VERSION ""

NS_ :

BS_:

BU_: CLUSTER FCU1 FCU2 FDC1 FDC2 HMS TBOX Tester VCU

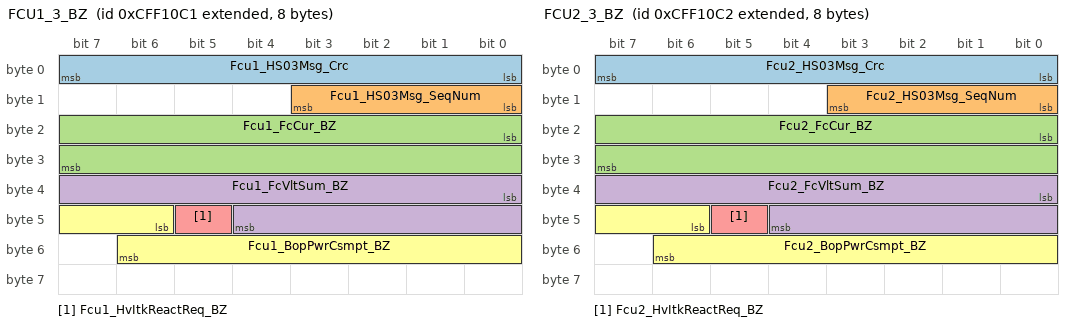
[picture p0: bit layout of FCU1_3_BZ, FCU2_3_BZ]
BO_ 2365526209 FCU1_3_BZ: 8 FCU1
 SG_ Fcu1_HS03Msg_Crc : 0|8@1+ (1,0) [0|255] "" VCU
 SG_ Fcu1_HS03Msg_SeqNum : 8|4@1+ (1,0) [0|15] "" VCU
 SG_ Fcu1_FcCur_BZ : 16|16@1+ (0.01,0) [0|655.35] "A" VCU
 SG_ Fcu1_FcVltSum_BZ : 32|13@1+ (0.1,0) [0|819.1] "V" VCU
 SG_ Fcu1_HvItkReactReq_BZ : 45|1@1+ (1,0) [0|1] "" VCU
 SG_ Fcu1_BopPwrCsmpt_BZ : 46|9@1+ (0.1,-5) [-5|46.1] "kW" VCU

BO_ 2365526210 FCU2_3_BZ: 8 FCU2
 SG_ Fcu2_HS03Msg_Crc : 0|8@1+ (1,0) [0|255] "" VCU
 SG_ Fcu2_HS03Msg_SeqNum : 8|4@1+ (1,0) [0|15] "" VCU
 SG_ Fcu2_FcCur_BZ : 16|16@1+ (0.01,0) [0|655.35] "A" VCU
 SG_ Fcu2_FcVltSum_BZ : 32|13@1+ (0.1,0) [0|819.1] "V" VCU
 SG_ Fcu2_HvItkReactReq_BZ : 45|1@1+ (1,0) [0|1] "" VCU
 SG_ Fcu2_BopPwrCsmpt_BZ : 46|9@1+ (0.1,-5) [-5|46.1] "kW" VCU

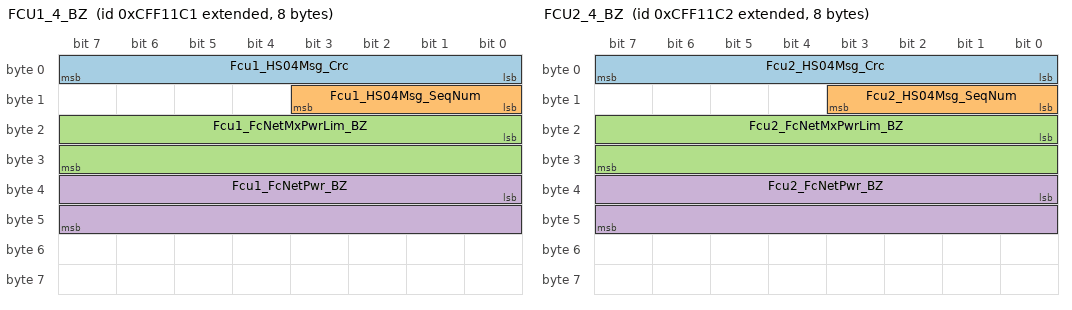
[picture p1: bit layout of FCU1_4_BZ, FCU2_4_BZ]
BO_ 2365526465 FCU1_4_BZ: 8 FCU1
 SG_ Fcu1_HS04Msg_Crc : 0|8@1+ (1,0) [0|255] "" VCU
 SG_ Fcu1_HS04Msg_SeqNum : 8|4@1+ (1,0) [0|15] "" VCU
 SG_ Fcu1_FcNetMxPwrLim_BZ : 16|16@1+ (0.1,0) [0|255] "kw" VCU
 SG_ Fcu1_FcNetPwr_BZ : 32|16@1+ (0.1,0) [0|255] "kw" VCU

BO_ 2365526466 FCU2_4_BZ: 8 FCU2
 SG_ Fcu2_HS04Msg_Crc : 0|8@1+ (1,0) [0|255] "" VCU
 SG_ Fcu2_HS04Msg_SeqNum : 8|4@1+ (1,0) [0|15] "" VCU
 SG_ Fcu2_FcNetMxPwrLim_BZ : 16|16@1+ (0.1,0) [0|255] "kw" VCU
 SG_ Fcu2_FcNetPwr_BZ : 32|16@1+ (0.1,0) [0|255] "kw" VCU

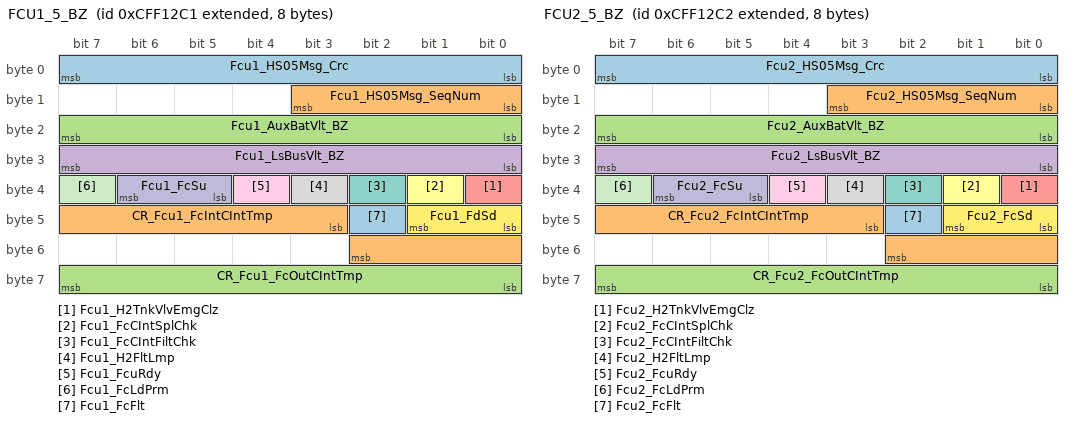
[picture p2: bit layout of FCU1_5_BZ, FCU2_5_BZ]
BO_ 2365526721 FCU1_5_BZ: 8 FCU1
 SG_ Fcu1_HS05Msg_Crc : 0|8@1+ (1,0) [0|255] "" VCU
 SG_ Fcu1_HS05Msg_SeqNum : 8|4@1+ (1,0) [0|15] "" VCU
 SG_ Fcu1_AuxBatVlt_BZ : 16|8@1+ (0.1,0) [0|25.5] "V" VCU
 SG_ Fcu1_LsBusVlt_BZ : 24|8@1+ (2,0) [0|510] "V" VCU
 SG_ Fcu1_H2TnkVlvEmgClz : 32|1@1+ (1,0) [0|1] "" VCU
 SG_ Fcu1_FcCIntSplChk : 33|1@1+ (1,0) [0|1] "" VCU
 SG_ Fcu1_FcCIntFiltChk : 34|1@1+ (1,0) [0|1] "" VCU
 SG_ Fcu1_H2FltLmp : 35|1@1+ (1,0) [0|1] "" VCU
 SG_ Fcu1_FcuRdy : 36|1@1+ (1,0) [0|1] "" VCU
 SG_ Fcu1_FcSu : 37|2@1+ (1,0) [0|1] "" VCU
 SG_ Fcu1_FcLdPrm : 39|1@1+ (1,0) [0|1] "" VCU
 SG_ Fcu1_FdSd : 40|2@1+ (1,0) [0|1] "" VCU
 SG_ Fcu1_FcFlt : 42|1@1+ (1,0) [0|1] "" VCU
 SG_ CR_Fcu1_FcIntCIntTmp : 43|8@1+ (1,0) [-128|127] "℃" VCU
 SG_ CR_Fcu1_FcOutCIntTmp : 56|8@1+ (1,0) [-128|127] "℃" VCU

BO_ 2365526722 FCU2_5_BZ: 8 FCU2
 SG_ Fcu2_HS05Msg_Crc : 0|8@1+ (1,0) [0|255] "" VCU
 SG_ Fcu2_HS05Msg_SeqNum : 8|4@1+ (1,0) [0|15] "" VCU
 SG_ Fcu2_AuxBatVlt_BZ : 16|8@1+ (0.1,0) [0|25.5] "V" VCU
 SG_ Fcu2_LsBusVlt_BZ : 24|8@1+ (2,0) [0|510] "V" VCU
 SG_ Fcu2_H2TnkVlvEmgClz : 32|1@1+ (1,0) [0|1] "" VCU
 SG_ Fcu2_FcCIntSplChk : 33|1@1+ (1,0) [0|1] "" VCU
 SG_ Fcu2_FcCIntFiltChk : 34|1@1+ (1,0) [0|1] "" VCU
 SG_ Fcu2_H2FltLmp : 35|1@1+ (1,0) [0|1] "" VCU
 SG_ Fcu2_FcuRdy : 36|1@1+ (1,0) [0|1] "" VCU
 SG_ Fcu2_FcSu : 37|2@1+ (1,0) [0|1] "" VCU
 SG_ Fcu2_FcLdPrm : 39|1@1+ (1,0) [0|1] "" VCU
 SG_ Fcu2_FcSd : 40|2@1+ (1,0) [0|1] "" VCU
 SG_ Fcu2_FcFlt : 42|1@1+ (1,0) [0|1] "" VCU
 SG_ CR_Fcu2_FcIntCIntTmp : 43|8@1+ (1,0) [-128|127] "℃" VCU
 SG_ CR_Fcu2_FcOutCIntTmp : 56|8@1+ (1,0) [-128|127] "℃" VCU

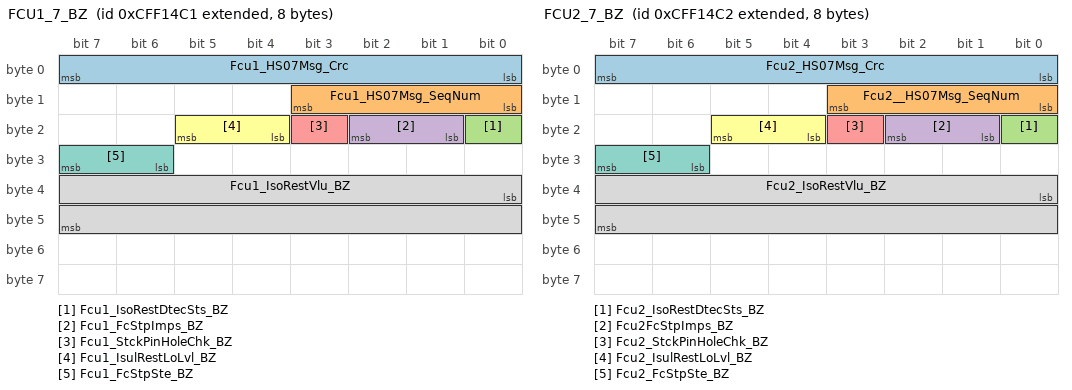
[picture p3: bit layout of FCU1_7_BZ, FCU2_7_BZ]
BO_ 2365527233 FCU1_7_BZ: 8 FCU1
 SG_ Fcu1_HS07Msg_Crc : 0|8@1+ (1,0) [0|255] "" VCU
 SG_ Fcu1_HS07Msg_SeqNum : 8|4@1+ (1,0) [0|15] "" VCU
 SG_ Fcu1_IsoRestDtecSts_BZ : 16|1@1+ (1,0) [0|1] "" VCU
 SG_ Fcu1_FcStpImps_BZ : 17|2@1+ (1,0) [0|3] "" VCU
 SG_ Fcu1_StckPinHoleChk_BZ : 19|1@1+ (1,0) [0|1] "" VCU
 SG_ Fcu1_IsulRestLoLvl_BZ : 20|2@1+ (1,0) [0|3] "" VCU
 SG_ Fcu1_FcStpSte_BZ : 30|2@1+ (1,0) [0|3] "" VCU
 SG_ Fcu1_IsoRestVlu_BZ : 32|16@1+ (1,0) [0|65535] "㏀" VCU

BO_ 2365527234 FCU2_7_BZ: 8 FCU2
 SG_ Fcu2_HS07Msg_Crc : 0|8@1+ (1,0) [0|255] "" VCU
 SG_ Fcu2__HS07Msg_SeqNum : 8|4@1+ (1,0) [0|15] "" VCU
 SG_ Fcu2_IsoRestDtecSts_BZ : 16|1@1+ (1,0) [0|1] "" VCU
 SG_ Fcu2FcStpImps_BZ : 17|2@1+ (1,0) [0|3] "" VCU
 SG_ Fcu2_StckPinHoleChk_BZ : 19|1@1+ (1,0) [0|1] "" VCU
 SG_ Fcu2_IsulRestLoLvl_BZ : 20|2@1+ (1,0) [0|3] "" VCU
 SG_ Fcu2_FcStpSte_BZ : 30|2@1+ (1,0) [0|3] "" VCU
 SG_ Fcu2_IsoRestVlu_BZ : 32|16@1+ (1,0) [0|65535] "㏀" VCU

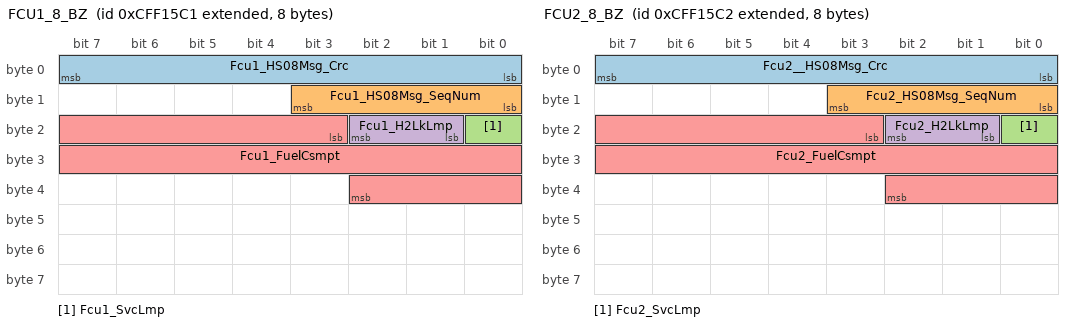
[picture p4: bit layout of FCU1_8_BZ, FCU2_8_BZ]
BO_ 2365527489 FCU1_8_BZ: 8 FCU1
 SG_ Fcu1_HS08Msg_Crc : 0|8@1+ (1,0) [0|255] "" VCU
 SG_ Fcu1_HS08Msg_SeqNum : 8|4@1+ (1,0) [0|15] "" VCU
 SG_ Fcu1_SvcLmp : 16|1@1+ (1,0) [0|1] "" VCU
 SG_ Fcu1_H2LkLmp : 17|2@1+ (1,0) [0|3] "" VCU
 SG_ Fcu1_FuelCsmpt : 19|16@1+ (0.01,0) [0|655.35] "mg" VCU

BO_ 2365527490 FCU2_8_BZ: 8 FCU2
 SG_ Fcu2__HS08Msg_Crc : 0|8@1+ (1,0) [0|255] "" VCU
 SG_ Fcu2_HS08Msg_SeqNum : 8|4@1+ (1,0) [0|15] "" VCU
 SG_ Fcu2_SvcLmp : 16|1@1+ (1,0) [0|1] "" VCU
 SG_ Fcu2_H2LkLmp : 17|2@1+ (1,0) [0|3] "" VCU
 SG_ Fcu2_FuelCsmpt : 19|16@1+ (0.01,0) [0|655.35] "mg" VCU

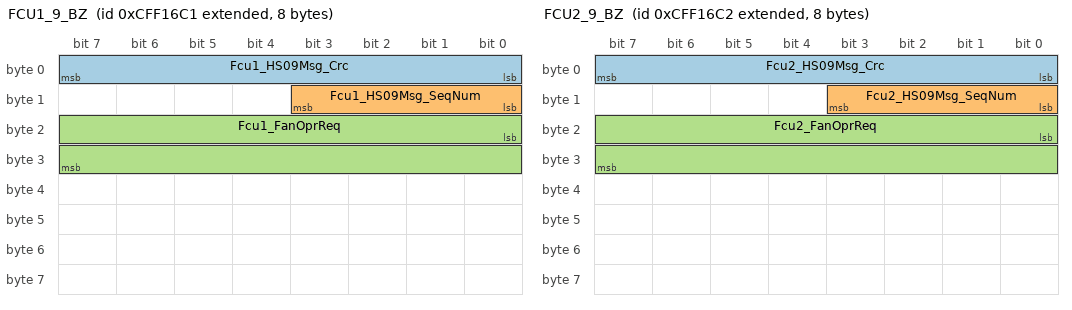
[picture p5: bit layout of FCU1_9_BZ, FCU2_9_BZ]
BO_ 2365527745 FCU1_9_BZ: 8 FCU1
 SG_ Fcu1_HS09Msg_Crc : 0|8@1+ (1,0) [0|255] "" VCU
 SG_ Fcu1_HS09Msg_SeqNum : 8|4@1+ (1,0) [0|15] "" VCU
 SG_ Fcu1_FanOprReq : 16|16@1+ (1,0) [0|100] "%" VCU

BO_ 2365527746 FCU2_9_BZ: 8 FCU2
 SG_ Fcu2_HS09Msg_Crc : 0|8@1+ (1,0) [0|255] "" VCU
 SG_ Fcu2_HS09Msg_SeqNum : 8|4@1+ (1,0) [0|15] "" VCU
 SG_ Fcu2_FanOprReq : 16|16@1+ (1,0) [0|100] "%" VCU

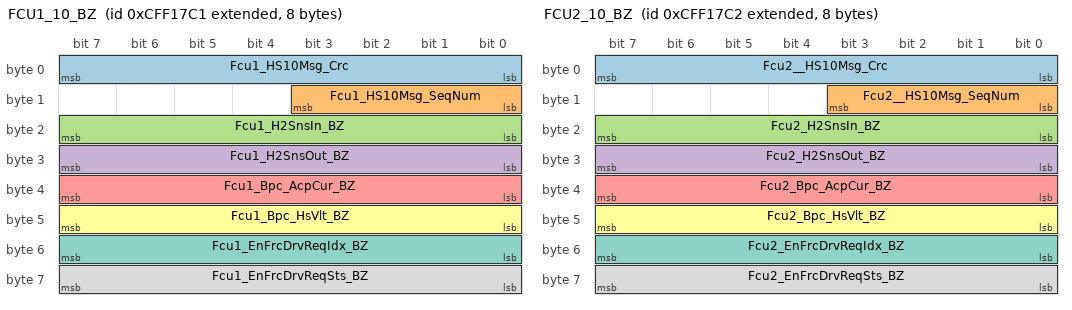
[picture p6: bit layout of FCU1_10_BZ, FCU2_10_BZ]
BO_ 2365528001 FCU1_10_BZ: 8 FCU1
 SG_ Fcu1_HS10Msg_Crc : 0|8@1+ (1,0) [0|255] "" VCU
 SG_ Fcu1_HS10Msg_SeqNum : 8|4@1+ (1,0) [0|15] "" VCU
 SG_ Fcu1_H2SnsIn_BZ : 16|8@1+ (0.02,0) [0|5.1] "%" VCU
 SG_ Fcu1_H2SnsOut_BZ : 24|8@1+ (0.02,0) [0|5.1] "%" VCU
 SG_ Fcu1_Bpc_AcpCur_BZ : 32|8@1+ (0.5,0) [-64|63.6] "A" VCU
 SG_ Fcu1_Bpc_HsVlt_BZ : 40|8@1+ (2,0) [0|510] "V" VCU
 SG_ Fcu1_EnFrcDrvReqIdx_BZ : 48|8@1+ (1,0) [0|255] "enum" VCU
 SG_ Fcu1_EnFrcDrvReqSts_BZ : 56|8@1+ (1,0) [0|255] "enum" VCU

BO_ 2365528002 FCU2_10_BZ: 8 FCU2
 SG_ Fcu2__HS10Msg_Crc : 0|8@1+ (1,0) [0|255] "" VCU
 SG_ Fcu2__HS10Msg_SeqNum : 8|4@1+ (1,0) [0|15] "" VCU
 SG_ Fcu2_H2SnsIn_BZ : 16|8@1+ (0.02,0) [0|5.1] "%" VCU
 SG_ Fcu2_H2SnsOut_BZ : 24|8@1+ (0.02,0) [0|5.1] "%" VCU
 SG_ Fcu2_Bpc_AcpCur_BZ : 32|8@1+ (0.5,0) [-64|63.6] "A" VCU
 SG_ Fcu2_Bpc_HsVlt_BZ : 40|8@1+ (2,0) [0|510] "V" VCU
 SG_ Fcu2_EnFrcDrvReqIdx_BZ : 48|8@1+ (1,0) [0|255] "enum" VCU
 SG_ Fcu2_EnFrcDrvReqSts_BZ : 56|8@1+ (1,0) [0|255] "enum" VCU

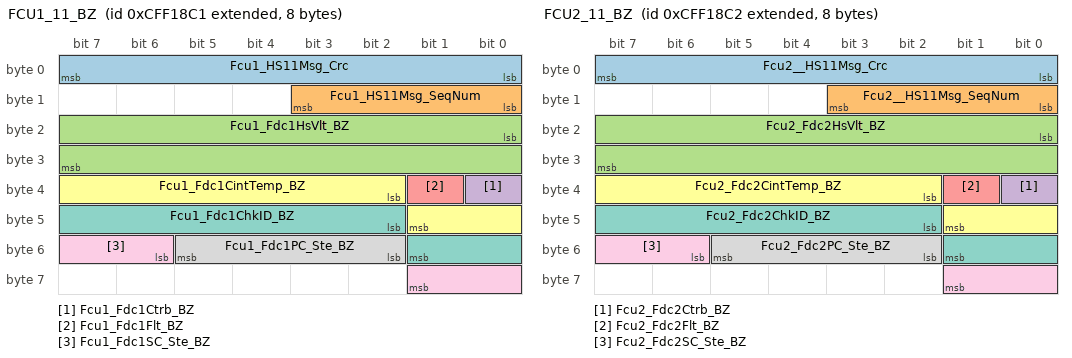
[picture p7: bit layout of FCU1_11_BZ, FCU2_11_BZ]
BO_ 2365528257 FCU1_11_BZ: 8 FCU1
 SG_ Fcu1_HS11Msg_Crc : 0|8@1+ (1,0) [0|255] "" VCU
 SG_ Fcu1_HS11Msg_SeqNum : 8|4@1+ (1,0) [0|15] "" VCU
 SG_ Fcu1_Fdc1HsVlt_BZ : 16|16@1+ (0.1,0) [0|1000] "" VCU
 SG_ Fcu1_Fdc1Ctrb_BZ : 32|1@1+ (1,0) [0|1] "" VCU
 SG_ Fcu1_Fdc1Flt_BZ : 33|1@1+ (1,0) [0|1] "" VCU
 SG_ Fcu1_Fdc1CintTemp_BZ : 34|8@1+ (1,-40) [-40|200] "" VCU
 SG_ Fcu1_Fdc1ChkID_BZ : 42|8@1+ (1,0) [0|255] "" VCU
 SG_ Fcu1_Fdc1PC_Ste_BZ : 50|4@1+ (1,0) [0|15] "" VCU
 SG_ Fcu1_Fdc1SC_Ste_BZ : 54|4@1+ (1,0) [0|15] "" VCU

BO_ 2365528258 FCU2_11_BZ: 8 FCU2
 SG_ Fcu2__HS11Msg_Crc : 0|8@1+ (1,0) [0|255] "" VCU
 SG_ Fcu2__HS11Msg_SeqNum : 8|4@1+ (1,0) [0|15] "" VCU
 SG_ Fcu2_Fdc2HsVlt_BZ : 16|16@1+ (0.1,0) [0|1000] "" VCU
 SG_ Fcu2_Fdc2Ctrb_BZ : 32|1@1+ (1,0) [0|1] "" VCU
 SG_ Fcu2_Fdc2Flt_BZ : 33|1@1+ (1,0) [0|1] "" VCU
 SG_ Fcu2_Fdc2CintTemp_BZ : 34|8@1+ (1,-40) [-40|200] "" VCU
 SG_ Fcu2_Fdc2ChkID_BZ : 42|8@1+ (1,0) [0|255] "" VCU
 SG_ Fcu2_Fdc2PC_Ste_BZ : 50|4@1+ (1,0) [0|15] "" VCU
 SG_ Fcu2_Fdc2SC_Ste_BZ : 54|4@1+ (1,0) [0|15] "" VCU

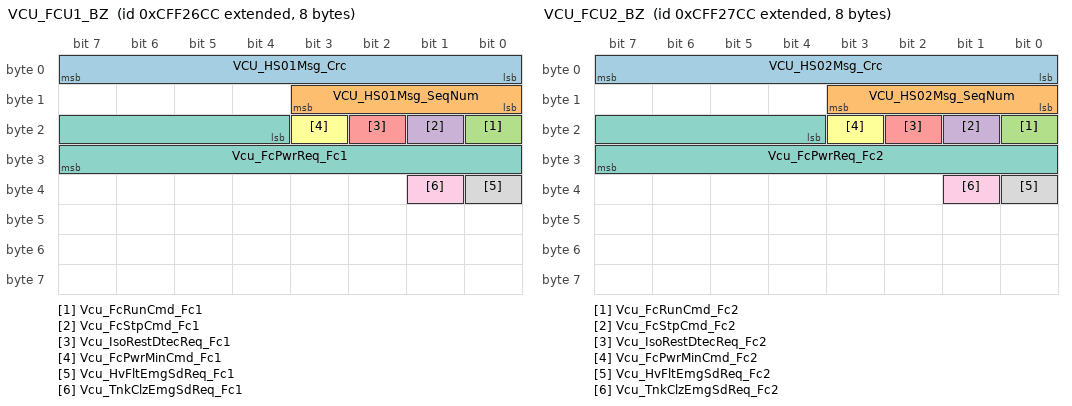
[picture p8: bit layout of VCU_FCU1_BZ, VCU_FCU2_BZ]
BO_ 2365531852 VCU_FCU1_BZ: 8 VCU
 SG_ VCU_HS01Msg_Crc : 0|8@1+ (1,0) [0|255] "" FCU1
 SG_ VCU_HS01Msg_SeqNum : 8|4@1+ (1,0) [0|15] "" FCU1
 SG_ Vcu_FcRunCmd_Fc1 : 16|1@1+ (1,0) [0|1] "" FCU1
 SG_ Vcu_FcStpCmd_Fc1 : 17|1@1+ (1,0) [0|1] "" FCU1
 SG_ Vcu_IsoRestDtecReq_Fc1 : 18|1@1+ (1,0) [0|1] "" FCU1
 SG_ Vcu_FcPwrMinCmd_Fc1 : 19|1@1+ (1,0) [0|1] "" FCU1
 SG_ Vcu_FcPwrReq_Fc1 : 20|12@1+ (0.1,0) [0|409.5] "kw" FCU1
 SG_ Vcu_HvFltEmgSdReq_Fc1 : 32|1@1+ (1,0) [0|1] "" FCU1
 SG_ Vcu_TnkClzEmgSdReq_Fc1 : 33|1@1+ (1,0) [0|1] "" FCU1

BO_ 2365532108 VCU_FCU2_BZ: 8 VCU
 SG_ VCU_HS02Msg_Crc : 0|8@1+ (1,0) [0|255] "" FCU2
 SG_ VCU_HS02Msg_SeqNum : 8|4@1+ (1,0) [0|15] "" FCU2
 SG_ Vcu_FcRunCmd_Fc2 : 16|1@1+ (1,0) [0|1] "" FCU2
 SG_ Vcu_FcStpCmd_Fc2 : 17|1@1+ (1,0) [0|1] "" FCU2
 SG_ Vcu_IsoRestDtecReq_Fc2 : 18|1@1+ (1,0) [0|1] "" FCU2
 SG_ Vcu_FcPwrMinCmd_Fc2 : 19|1@1+ (1,0) [0|1] "" FCU2
 SG_ Vcu_FcPwrReq_Fc2 : 20|12@1+ (0.1,0) [0|409.5] "kw" FCU2
 SG_ Vcu_HvFltEmgSdReq_Fc2 : 32|1@1+ (1,0) [0|1] "" FCU2
 SG_ Vcu_TnkClzEmgSdReq_Fc2 : 33|1@1+ (1,0) [0|1] "" FCU2

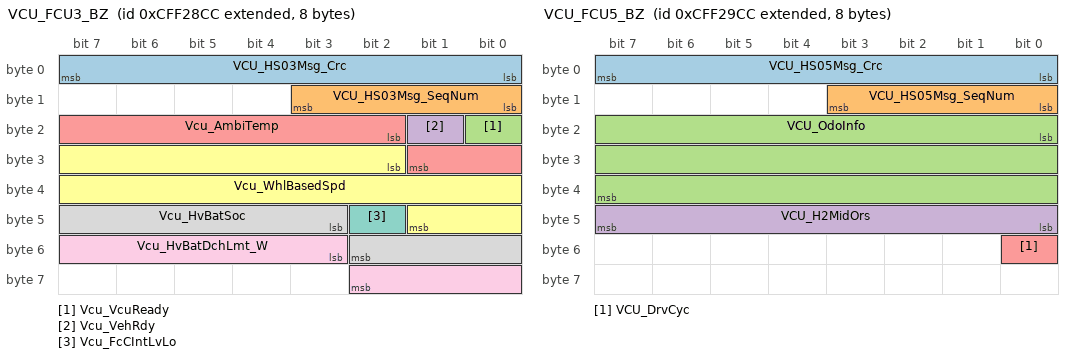
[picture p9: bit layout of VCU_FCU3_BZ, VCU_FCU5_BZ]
BO_ 2365532364 VCU_FCU3_BZ: 8 VCU
 SG_ VCU_HS03Msg_Crc : 0|8@1+ (1,0) [0|255] "" FCU1
 SG_ VCU_HS03Msg_SeqNum : 8|4@1+ (1,0) [0|15] "" FCU1
 SG_ Vcu_VcuReady : 16|1@1+ (1,0) [0|1] "" FCU2
 SG_ Vcu_VehRdy : 17|1@1+ (1,0) [0|1] "" FCU2
 SG_ Vcu_AmbiTemp : 18|8@1+ (1,-40) [-40|215] "℃" FCU2
 SG_ Vcu_WhlBasedSpd : 26|16@1+ (0.00390625,0) [0|250.996] "km/h" FCU2
 SG_ Vcu_FcCIntLvLo : 42|1@1+ (1,0) [0|1] "" FCU2
 SG_ Vcu_HvBatSoc : 43|8@1+ (0.5,0) [0|100] "%" FCU2
 SG_ Vcu_HvBatDchLmt_W : 51|8@1+ (2000,0) [0|500000] "W" FCU2

BO_ 2365532620 VCU_FCU5_BZ: 8 VCU
 SG_ VCU_HS05Msg_Crc : 0|8@1+ (1,0) [0|255] "" FCU1
 SG_ VCU_HS05Msg_SeqNum : 8|4@1+ (1,0) [0|15] "" FCU1
 SG_ VCU_OdoInfo : 16|24@1+ (1,0) [0|15999999] "hr" Vector__XXX
 SG_ VCU_H2MidOrs : 40|8@1+ (1,0) [0|5100] "" Vector__XXX
 SG_ VCU_DrvCyc : 48|1@1+ (1,0) [0|1] "" Vector__XXX

BO_ 2499748079 TX_MSG_CAN2: 8 VCU
 SG_ Signal_TX_CAN2 : 0|64@1+ (1,0) [0|1] "" Vector__XXX

BO_ 2499748089 RX_MSG_CAN2: 8 Tester
 SG_ Signal_RX_CAN2 : 0|64@1+ (1,0) [0|1] "" VCU

BO_ 2565530785 VIN_RQST: 8 TBOX
 SG_ TBOX_VIN_Req : 0|16@1+ (1,0) [0|65535] "" Vector__XXX

BO_ 2565603265 TPDT_FCU1: 8 FCU1
 SG_ SequenceNum_FCU1 : 0|8@1+ (1,0) [0|255] "" VCU
 SG_ PacketizedData_FCU1 : 8|56@1+ (1,0) [0|7.20575940379279e+16] "" VCU

BO_ 2565603266 TPDT_FCU2: 8 FCU2
 SG_ SequenceNum_FCU2 : 0|8@1+ (1,0) [0|255] "" VCU
 SG_ PacketizedData_FCU2 : 8|56@1+ (1,0) [0|7.20575940379279e+16] "" VCU

BO_ 2565603311 TPDT_VCU_bsw: 8 VCU
 SG_ SequenceNum_VCU_bsw : 0|8@1+ (1,0) [0|252] "" Vector__XXX
 SG_ PacketizedData_VCU_bsw : 8|56@1+ (1,0) [0|0] "" Vector__XXX

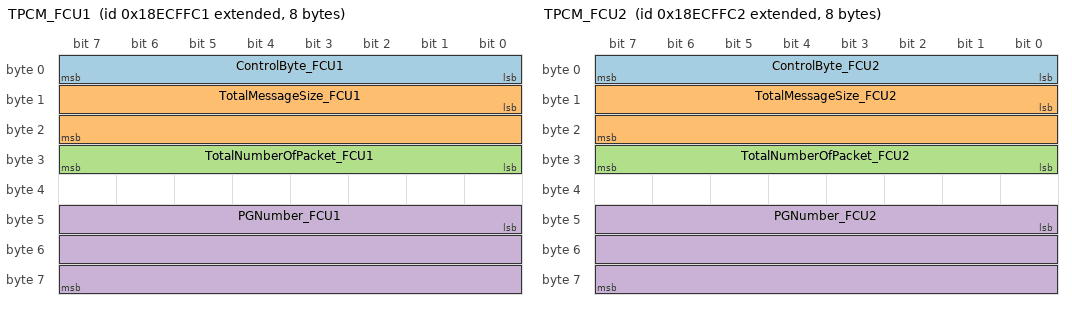
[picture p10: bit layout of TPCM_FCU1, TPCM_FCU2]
BO_ 2565668801 TPCM_FCU1: 8 FCU1
 SG_ ControlByte_FCU1 : 0|8@1+ (1,0) [0|255] "" VCU
 SG_ TotalMessageSize_FCU1 : 8|16@1+ (1,0) [0|0] "" VCU
 SG_ TotalNumberOfPacket_FCU1 : 24|8@1+ (1,0) [0|0] "" VCU
 SG_ PGNumber_FCU1 : 40|24@1+ (1,0) [0|16777200] "" VCU

BO_ 2565668802 TPCM_FCU2: 8 FCU2
 SG_ ControlByte_FCU2 : 0|8@1+ (1,0) [0|255] "" VCU
 SG_ TotalMessageSize_FCU2 : 8|16@1+ (1,0) [0|255] "" VCU
 SG_ TotalNumberOfPacket_FCU2 : 24|8@1+ (1,0) [0|65535] "" VCU
 SG_ PGNumber_FCU2 : 40|24@1+ (1,0) [0|16777200] "" VCU

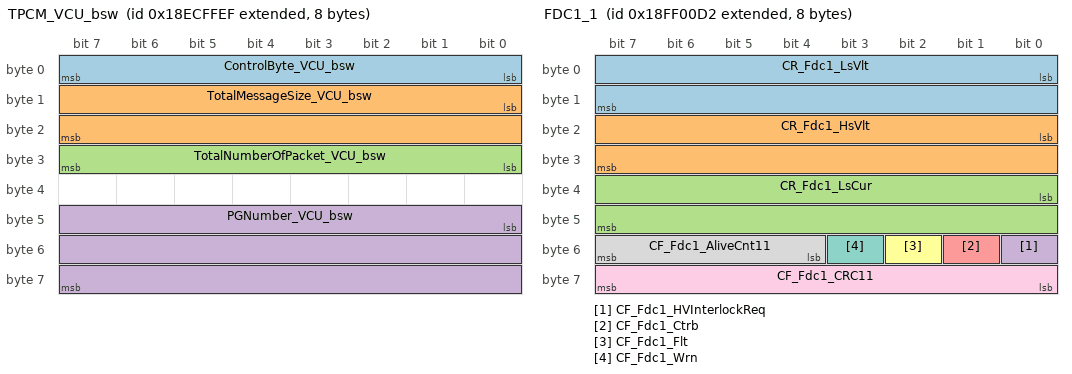
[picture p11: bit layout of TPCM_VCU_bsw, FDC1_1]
BO_ 2565668847 TPCM_VCU_bsw: 8 VCU
 SG_ ControlByte_VCU_bsw : 0|8@1+ (1,0) [0|255] "" Vector__XXX
 SG_ TotalMessageSize_VCU_bsw : 8|16@1+ (1,0) [0|0] "" Vector__XXX
 SG_ TotalNumberOfPacket_VCU_bsw : 24|8@1+ (1,0) [0|0] "" Vector__XXX
 SG_ PGNumber_VCU_bsw : 40|24@1+ (1,0) [0|16777200] "" Vector__XXX

BO_ 2566834881 DM1_FCU1: 18 FCU1
 SG_ ProtectedLampStatus_FCU1 : 0|2@1+ (1,0) [0|3] "" CLUSTER
 SG_ AmberWarningLampStatus_FCU1 : 2|2@1+ (1,0) [0|3] "" CLUSTER
 SG_ RedStopLampState_FCU1 : 4|2@1+ (1,0) [0|3] "" CLUSTER
 SG_ MalFunIndiLampStatus_FCU1 : 6|2@1+ (1,0) [0|3] "" CLUSTER
 SG_ FlashProtectLamp_FCU1 : 8|2@1+ (1,0) [0|3] "" CLUSTER
 SG_ FlashAmberWarningLamp_FCU1 : 10|2@1+ (1,0) [0|3] "" CLUSTER
 SG_ FlashRedStopLamp_FCU1 : 12|2@1+ (1,0) [0|3] "" CLUSTER
 SG_ FlashMalFunIndiLamp_FCU1 : 14|2@1+ (1,0) [0|3] "" CLUSTER
 SG_ DTC1_FCU1 : 16|32@1+ (1,0) [0|4294967295] "" CLUSTER
 SG_ DTC2_FCU1 : 48|32@1+ (1,0) [0|4294967295] "" CLUSTER
 SG_ DTC3_FCU1 : 80|32@1+ (1,0) [0|4294967295] "" CLUSTER
 SG_ DTC4_FCU1 : 112|32@1+ (1,0) [0|4294967295] "" CLUSTER

BO_ 2566834882 DM1_FCU2: 18 FCU2
 SG_ ProtectedLampStatus_FCU2 : 0|2@1+ (1,0) [0|3] "" CLUSTER
 SG_ AmberWarningLampStatus_FCU2 : 2|2@1+ (1,0) [0|3] "" CLUSTER
 SG_ RedStopLampState_FCU2 : 4|2@1+ (1,0) [0|3] "" CLUSTER
 SG_ MalFunIndiLampStatus_FCU2 : 6|2@1+ (1,0) [0|3] "" CLUSTER
 SG_ FlashProtectLamp_FCU2 : 8|2@1+ (1,0) [0|3] "" CLUSTER
 SG_ FlashAmberWarningLamp_FCU2 : 10|2@1+ (1,0) [0|3] "" CLUSTER
 SG_ FlashRedStopLamp_FCU2 : 12|2@1+ (1,0) [0|3] "" CLUSTER
 SG_ FlashMalFunIndiLamp_FCU2 : 14|2@1+ (1,0) [0|3] "" CLUSTER
 SG_ DTC1_FCU2 : 16|32@1+ (1,0) [0|4294967295] "" CLUSTER
 SG_ DTC2_FCU2 : 48|32@1+ (1,0) [0|4294967295] "" CLUSTER
 SG_ DTC3_FCU2 : 80|32@1+ (1,0) [0|4294967295] "" CLUSTER
 SG_ DTC4_FCU2 : 112|32@1+ (1,0) [0|4294967295] "" CLUSTER

BO_ 2566843631 VI: 21 VCU
 SG_ VINData : 0|64@1+ (1,0) [0|65535] "" Vector__XXX

BO_ 2566848722 FDC1_1: 8 FDC1
 SG_ CR_Fdc1_LsVlt : 0|16@1+ (0.1,0) [0|1000] "" VCU
 SG_ CR_Fdc1_HsVlt : 16|16@1+ (0.1,0) [0|1000] "" VCU
 SG_ CR_Fdc1_LsCur : 32|16@1+ (0.1,0) [-500|500] "" VCU
 SG_ CF_Fdc1_HVInterlockReq : 48|1@1+ (1,0) [0|1] "" VCU
 SG_ CF_Fdc1_Ctrb : 49|1@1+ (1,0) [0|1] "" VCU
 SG_ CF_Fdc1_Flt : 50|1@1+ (1,0) [0|1] "" VCU
 SG_ CF_Fdc1_Wrn : 51|1@1+ (1,0) [0|1] "" VCU
 SG_ CF_Fdc1_AliveCnt11 : 52|4@1+ (1,0) [0|15] "" VCU
 SG_ CF_Fdc1_CRC11 : 56|8@1+ (1,0) [0|255] "" VCU

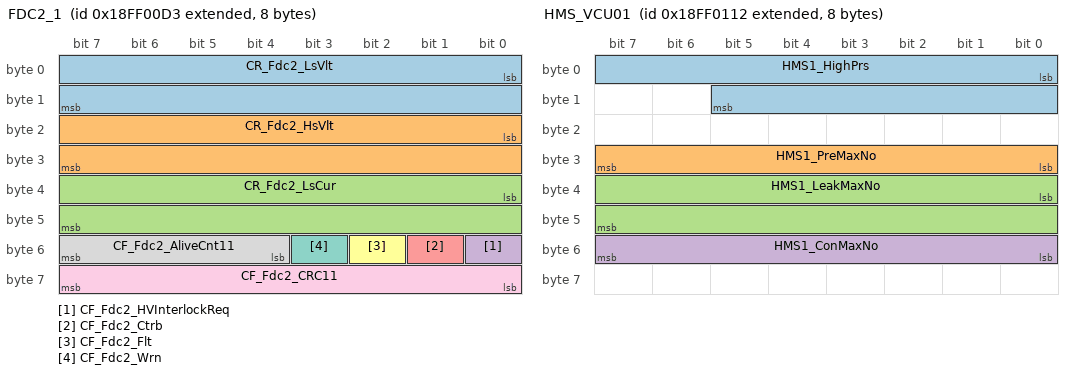
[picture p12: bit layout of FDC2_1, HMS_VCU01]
BO_ 2566848723 FDC2_1: 8 FDC2
 SG_ CR_Fdc2_LsVlt : 0|16@1+ (0.1,0) [0|1000] "" VCU
 SG_ CR_Fdc2_HsVlt : 16|16@1+ (0.1,0) [0|1000] "" VCU
 SG_ CR_Fdc2_LsCur : 32|16@1+ (0.1,0) [-500|500] "" VCU
 SG_ CF_Fdc2_HVInterlockReq : 48|1@1+ (1,0) [0|1] "" VCU
 SG_ CF_Fdc2_Ctrb : 49|1@1+ (1,0) [0|1] "" VCU
 SG_ CF_Fdc2_Flt : 50|1@1+ (1,0) [0|1] "" VCU
 SG_ CF_Fdc2_Wrn : 51|1@1+ (1,0) [0|1] "" VCU
 SG_ CF_Fdc2_AliveCnt11 : 52|4@1+ (1,0) [0|15] "" VCU
 SG_ CF_Fdc2_CRC11 : 56|8@1+ (1,0) [0|255] "" VCU

BO_ 2566848786 HMS_VCU01: 8 HMS
 SG_ HMS1_HighPrs : 0|14@1+ (0.01,0) [0|5000] "Mpa" VCU
 SG_ HMS1_PreMaxNo : 24|8@1+ (1,0) [0|252] "" VCU
 SG_ HMS1_LeakMaxNo : 32|16@1+ (1,0) [0|60000] "mg/kg" VCU
 SG_ HMS1_ConMaxNo : 48|8@1+ (1,0) [0|252] "" VCU

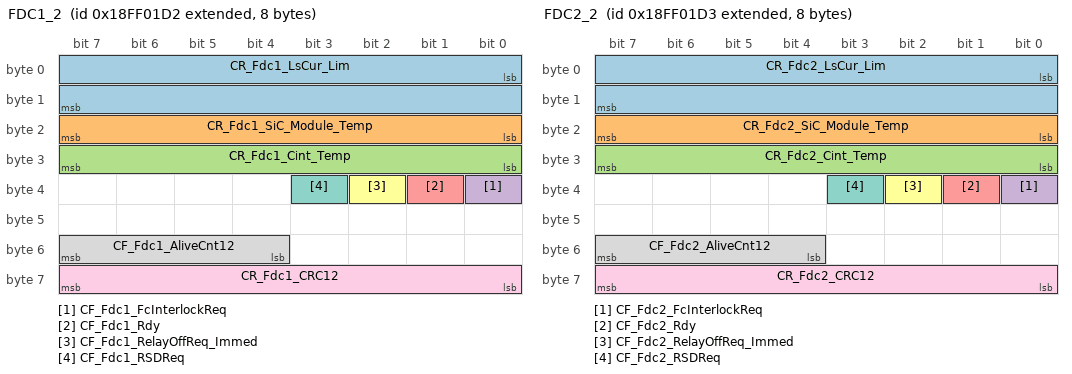
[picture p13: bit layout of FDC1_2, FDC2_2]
BO_ 2566848978 FDC1_2: 8 FDC1
 SG_ CR_Fdc1_LsCur_Lim : 0|16@1+ (0.1,0) [0|255] "" VCU
 SG_ CR_Fdc1_SiC_Module_Temp : 16|8@1+ (1,-40) [-40|200] "" VCU
 SG_ CR_Fdc1_Cint_Temp : 24|8@1+ (1,-40) [-40|200] "" VCU
 SG_ CF_Fdc1_FcInterlockReq : 32|1@1+ (1,0) [0|1] "" VCU
 SG_ CF_Fdc1_Rdy : 33|1@1+ (1,0) [0|1] "" VCU
 SG_ CF_Fdc1_RelayOffReq_Immed : 34|1@1+ (1,0) [0|1] "" VCU
 SG_ CF_Fdc1_RSDReq : 35|1@1+ (1,0) [0|1] "" VCU
 SG_ CF_Fdc1_AliveCnt12 : 52|4@1+ (1,0) [0|15] "" VCU
 SG_ CR_Fdc1_CRC12 : 56|8@1+ (1,0) [0|255] "" VCU

BO_ 2566848979 FDC2_2: 8 FDC2
 SG_ CR_Fdc2_LsCur_Lim : 0|16@1+ (0.1,0) [0|255] "" VCU
 SG_ CR_Fdc2_SiC_Module_Temp : 16|8@1+ (1,-40) [-40|200] "" VCU
 SG_ CR_Fdc2_Cint_Temp : 24|8@1+ (1,-40) [-40|200] "" VCU
 SG_ CF_Fdc2_FcInterlockReq : 32|1@1+ (1,0) [0|1] "" VCU
 SG_ CF_Fdc2_Rdy : 33|1@1+ (1,0) [0|1] "" VCU
 SG_ CF_Fdc2_RelayOffReq_Immed : 34|1@1+ (1,0) [0|1] "" VCU
 SG_ CF_Fdc2_RSDReq : 35|1@1+ (1,0) [0|1] "" VCU
 SG_ CF_Fdc2_AliveCnt12 : 52|4@1+ (1,0) [0|15] "" VCU
 SG_ CR_Fdc2_CRC12 : 56|8@1+ (1,0) [0|255] "" VCU

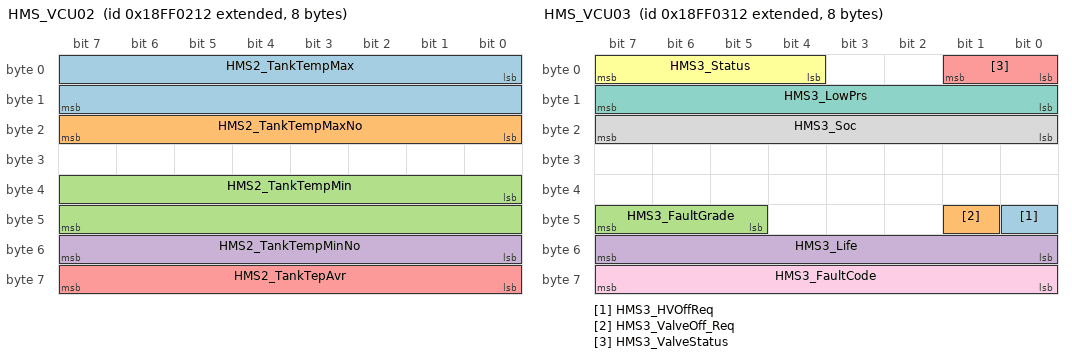
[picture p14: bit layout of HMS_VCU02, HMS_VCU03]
BO_ 2566849042 HMS_VCU02: 8 HMS
 SG_ HMS2_TankTempMax : 0|16@1+ (0.1,-40) [-40|2400] "degC" VCU
 SG_ HMS2_TankTempMaxNo : 16|8@1+ (1,0) [0|252] "" VCU
 SG_ HMS2_TankTempMin : 32|16@1+ (0.1,-40) [-40|2400] "degC" VCU
 SG_ HMS2_TankTempMinNo : 48|8@1+ (1,0) [0|252] "" VCU
 SG_ HMS2_TankTepAvr : 56|8@1+ (0.1,-40) [-40|2400] "degC" VCU

BO_ 2566849298 HMS_VCU03: 8 HMS
 SG_ HMS3_HVOffReq : 40|1@1+ (1,0) [0|1] "" VCU
 SG_ HMS3_ValveOff_Req : 41|1@1+ (1,0) [0|1] "" VCU
 SG_ HMS3_FaultGrade : 45|3@1+ (1,0) [0|255] "" VCU
 SG_ HMS3_Life : 48|8@1+ (1,0) [0|255] "" VCU
 SG_ HMS3_ValveStatus : 0|2@1+ (1,0) [0|3] "" VCU
 SG_ HMS3_Status : 4|4@1+ (1,0) [0|15] "" VCU
 SG_ HMS3_LowPrs : 8|8@1+ (0.01,0) [0|250] "Mpa" VCU
 SG_ HMS3_Soc : 16|8@1+ (1,0) [0|100] "%/bit" VCU
 SG_ HMS3_FaultCode : 56|8@1+ (1,0) [0|255] "" VCU

BO_ 2566849810 HMS_VCU05: 8 HMS
 SG_ HMS5_HyMassAvailable : 32|16@1+ (0.01,0) [0|655.35] "kg" VCU

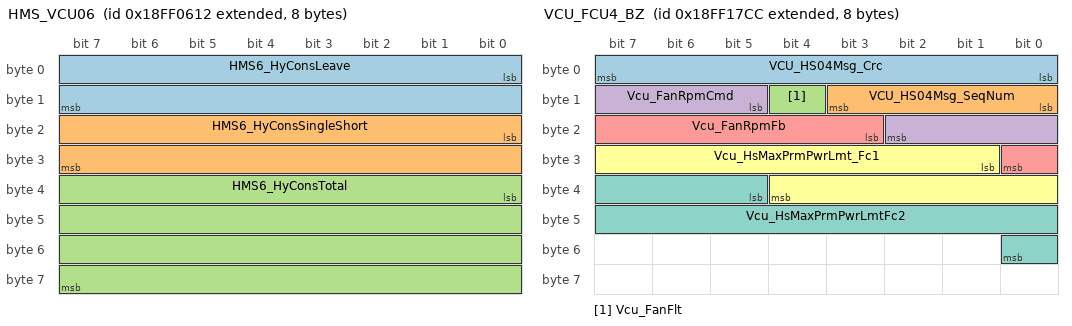
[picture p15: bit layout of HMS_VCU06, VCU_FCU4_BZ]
BO_ 2566850066 HMS_VCU06: 8 HMS
 SG_ HMS6_HyConsLeave : 0|16@1+ (0.01,0) [0|655.35] "kg" VCU
 SG_ HMS6_HyConsSingleShort : 16|16@1+ (0.01,0) [0|655.35] "kg" VCU
 SG_ HMS6_HyConsTotal : 32|32@1+ (0.01,0) [0|4294967295] "kg" VCU

BO_ 2566854604 VCU_FCU4_BZ: 8 VCU
 SG_ VCU_HS04Msg_Crc : 0|8@1+ (1,0) [0|255] "" FCU2
 SG_ VCU_HS04Msg_SeqNum : 8|4@1+ (1,0) [0|15] "" FCU2
 SG_ Vcu_FanFlt : 12|1@1+ (1,0) [0|1] "" Vector__XXX
 SG_ Vcu_FanRpmCmd : 13|6@1+ (100,0) [0|5000] "rpm" Vector__XXX
 SG_ Vcu_FanRpmFb : 19|6@1+ (100,0) [0|5000] "rpm" Vector__XXX
 SG_ Vcu_HsMaxPrmPwrLmt_Fc1 : 25|12@1+ (0.1,0) [0|255] "kw" FCU1
 SG_ Vcu_HsMaxPrmPwrLmtFc2 : 37|12@1+ (0.1,0) [0|255] "kw" FCU2

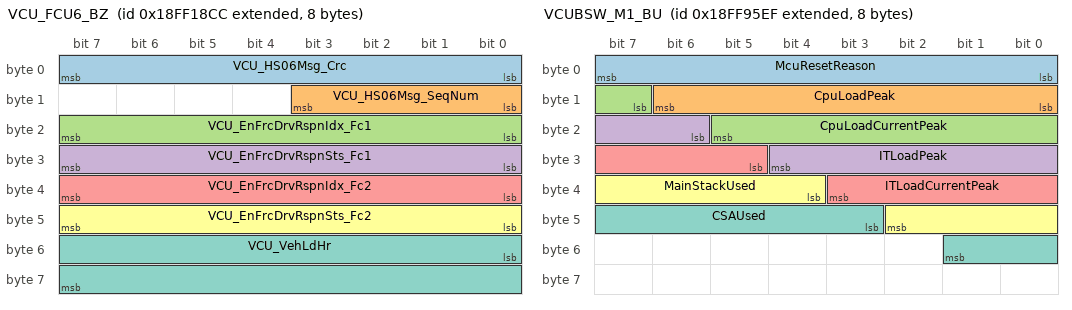
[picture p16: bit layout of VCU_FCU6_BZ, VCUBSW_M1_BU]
BO_ 2566854860 VCU_FCU6_BZ: 8 VCU
 SG_ VCU_HS06Msg_Crc : 0|8@1+ (1,0) [0|255] "" FCU1,FCU2
 SG_ VCU_HS06Msg_SeqNum : 8|4@1+ (1,0) [0|15] "" FCU1,FCU2
 SG_ VCU_EnFrcDrvRspnIdx_Fc1 : 16|8@1+ (1,0) [0|255] "" FCU1
 SG_ VCU_EnFrcDrvRspnSts_Fc1 : 24|8@1+ (1,0) [0|15] "" FCU1
 SG_ VCU_EnFrcDrvRspnIdx_Fc2 : 32|8@1+ (1,0) [0|255] "" FCU2
 SG_ VCU_EnFrcDrvRspnSts_Fc2 : 40|8@1+ (1,0) [0|255] "" FCU2
 SG_ VCU_VehLdHr : 48|16@1+ (1,0) [0|65535] "" FCU1,FCU2

BO_ 2566865647 VCU_VehSte: 8 VCU
 SG_ VCU_DrvCyc_CF : 32|1@1+ (1,0) [0|1] "" FCU1,FCU2
 SG_ VCU_WarmUpCyc_VF : 33|1@1+ (1,0) [0|255] "" FCU1,FCU2

BO_ 2566886895 VCUBSW_M1_BU: 8 VCU
 SG_ McuResetReason : 0|8@1+ (1,0) [0|255] "" Vector__XXX
 SG_ CpuLoadPeak : 8|7@1+ (1,0) [0|127] "" Vector__XXX
 SG_ CpuLoadCurrentPeak : 15|7@1+ (1,0) [0|127] "" Vector__XXX
 SG_ ITLoadPeak : 22|7@1+ (1,0) [0|127] "" Vector__XXX
 SG_ ITLoadCurrentPeak : 29|7@1+ (1,0) [0|127] "" Vector__XXX
 SG_ MainStackUsed : 36|7@1+ (1,0) [0|127] "" Vector__XXX
 SG_ CSAUsed : 43|7@1+ (1,0) [0|100] "" Vector__XXX

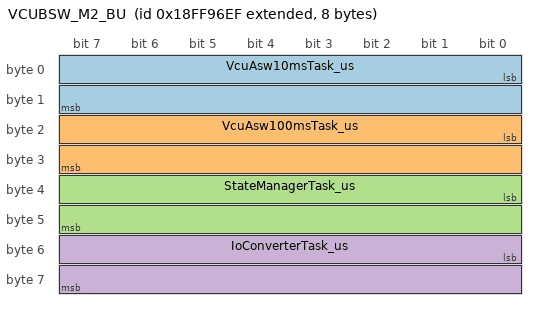
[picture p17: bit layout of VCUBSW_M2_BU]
BO_ 2566887151 VCUBSW_M2_BU: 8 VCU
 SG_ VcuAsw10msTask_us : 0|16@1+ (1,0) [0|65535] "" Vector__XXX
 SG_ VcuAsw100msTask_us : 16|16@1+ (1,0) [0|65535] "" Vector__XXX
 SG_ StateManagerTask_us : 32|16@1+ (1,0) [0|65535] "" Vector__XXX
 SG_ IoConverterTask_us : 48|16@1+ (1,0) [0|65535] "" Vector__XXX

BO_ 2583626017 VCU_HMS01: 8 VCU
 SG_ FCU_HMSEn : 0|2@1+ (1,0) [0|3] "" HMS

CM_ SG_ 2365526209 Fcu1_HS03Msg_Crc "Crc Signal for E2E Protection";
CM_ SG_ 2365526209 Fcu1_BopPwrCsmpt_BZ "연료전지스택보기류출력값";
CM_ SG_ 2365526465 Fcu1_HS04Msg_Crc "Crc Signal for E2E Protection";
CM_ SG_ 2365526721 Fcu1_HS05Msg_Crc "Crc Signal for E2E Protection";
CM_ SG_ 2365527233 Fcu1_HS07Msg_Crc "Crc Signal for E2E Protection";
CM_ SG_ 2365527489 Fcu1_HS08Msg_Crc "Crc Signal for E2E Protection";
CM_ SG_ 2365527489 Fcu1_SvcLmp "고장Lamp";
CM_ SG_ 2365527489 Fcu1_H2LkLmp "수소누출Lamp";
CM_ SG_ 2365527489 Fcu1_FuelCsmpt "수소소모량";
CM_ SG_ 2365527745 Fcu1_HS09Msg_Crc "Crc Signal for E2E Protection";
CM_ SG_ 2365527745 Fcu1_FanOprReq "Radiator Fan 구동요구량";
CM_ SG_ 2365528001 Fcu1_HS10Msg_Crc "Crc Signal for E2E Protection";
CM_ SG_ 2365528001 Fcu1_H2SnsIn_BZ "Hydrogen concentrate sensor value inside the enclosure";
CM_ SG_ 2365528001 Fcu1_H2SnsOut_BZ "Hydrogen concentrate sensor value outside the enclosure";
CM_ SG_ 2365528001 Fcu1_Bpc_AcpCur_BZ "Air blower current";
CM_ SG_ 2365528001 Fcu1_Bpc_HsVlt_BZ "BPCU High Side Voltage";
CM_ SG_ 2365528001 Fcu1_EnFrcDrvReqIdx_BZ "Emforce Drive Request Index";
CM_ SG_ 2365528001 Fcu1_EnFrcDrvReqSts_BZ "Emforce Drive Request Status";
CM_ SG_ 2365528257 Fcu1_HS11Msg_Crc "Crc Signal for E2E Protection";
CM_ SG_ 2365528257 Fcu1_Fdc1CintTemp_BZ "Fdc1 Coolant Temperature";
CM_ SG_ 2566834881 ProtectedLampStatus_FCU1 "PL:ProtectLamp(보호등)";
CM_ SG_ 2566834881 AmberWarningLampStatus_FCU1 "AWL:호박등";
CM_ SG_ 2566834881 RedStopLampState_FCU1 "RSL:적색등";
CM_ SG_ 2566834881 MalFunIndiLampStatus_FCU1 "MIL:고장지시등";
CM_ SG_ 2566834881 FlashProtectLamp_FCU1 "PL:ProtectLamp(보호등)";
CM_ SG_ 2566834881 FlashAmberWarningLamp_FCU1 "AWL:호박등";
CM_ SG_ 2566834881 FlashRedStopLamp_FCU1 "RSL:적색등";
CM_ SG_ 2566834881 FlashMalFunIndiLamp_FCU1 "MIL:고장지시등";
CM_ SG_ 2565668801 ControlByte_FCU1 "ControlByte:Connection Mode(Broadcast announce message reserved value:0x32)";
CM_ SG_ 2565668801 TotalMessageSize_FCU1 "Total message size";
CM_ SG_ 2565668801 TotalNumberOfPacket_FCU1 "Total message packet";
CM_ SG_ 2565668801 PGNumber_FCU1 "Parameter Group Number(FCU:FECAh)";
CM_ SG_ 2565603265 SequenceNum_FCU1 "TP_DT(Transport Protocol Data Transfer)-Package Identification";
CM_ SG_ 2565603265 PacketizedData_FCU1 "TP_DT message data";
CM_ SG_ 2365526210 Fcu2_HS03Msg_Crc "Crc Signal for E2E Protection";
CM_ SG_ 2365526210 Fcu2_BopPwrCsmpt_BZ "연료전지스택보기류출력값";
CM_ SG_ 2365526466 Fcu2_HS04Msg_Crc "Crc Signal for E2E Protection";
CM_ SG_ 2365526722 Fcu2_HS05Msg_Crc "Crc Signal for E2E Protection";
CM_ SG_ 2365527234 Fcu2_HS07Msg_Crc "Crc Signal for E2E Protection";
CM_ SG_ 2365527490 Fcu2__HS08Msg_Crc "Crc Signal for E2E Protection";
CM_ SG_ 2365527490 Fcu2_SvcLmp "고장Lamp";
CM_ SG_ 2365527490 Fcu2_H2LkLmp "수소누출Lamp";
CM_ SG_ 2365527490 Fcu2_FuelCsmpt "수소소모량";
CM_ SG_ 2365527746 Fcu2_HS09Msg_Crc "Crc Signal for E2E Protection";
CM_ SG_ 2365527746 Fcu2_FanOprReq "Radiator Fan 구동요구량";
CM_ SG_ 2365528002 Fcu2__HS10Msg_Crc "Crc Signal for E2E Protection";
CM_ SG_ 2365528002 Fcu2_H2SnsIn_BZ "Hydrogen concentrate sensor value inside the enclosure";
CM_ SG_ 2365528002 Fcu2_H2SnsOut_BZ "Hydrogen concentrate sensor value outside the enclosure";
CM_ SG_ 2365528002 Fcu2_Bpc_AcpCur_BZ "Air blower current";
CM_ SG_ 2365528002 Fcu2_Bpc_HsVlt_BZ "BPCU High Side Voltage";
CM_ SG_ 2365528002 Fcu2_EnFrcDrvReqIdx_BZ "Emforce Drive Request Index";
CM_ SG_ 2365528002 Fcu2_EnFrcDrvReqSts_BZ "Emforce Drive Request Status";
CM_ SG_ 2365528258 Fcu2__HS11Msg_Crc "Crc Signal for E2E Protection";
CM_ SG_ 2365528258 Fcu2_Fdc2CintTemp_BZ "FdC2 Coolant Temperature";
CM_ SG_ 2566834882 ProtectedLampStatus_FCU2 "PL:ProtectLamp(보호등)";
CM_ SG_ 2566834882 AmberWarningLampStatus_FCU2 "AWL:호박등";
CM_ SG_ 2566834882 RedStopLampState_FCU2 "RSL:적색등";
CM_ SG_ 2566834882 MalFunIndiLampStatus_FCU2 "MIL:고장지시등";
CM_ SG_ 2566834882 FlashProtectLamp_FCU2 "PL:ProtectLamp(보호등)";
CM_ SG_ 2566834882 FlashAmberWarningLamp_FCU2 "AWL:호박등";
CM_ SG_ 2566834882 FlashRedStopLamp_FCU2 "RSL:적색등";
CM_ SG_ 2566834882 FlashMalFunIndiLamp_FCU2 "MIL:고장지시등";
CM_ SG_ 2565668802 ControlByte_FCU2 "ControlByte:Connection Mode(Broadcast announce message reserved value:0x32)";
CM_ SG_ 2565668802 TotalMessageSize_FCU2 "Total message size";
CM_ SG_ 2565668802 TotalNumberOfPacket_FCU2 "Total message packet";
CM_ SG_ 2565668802 PGNumber_FCU2 "Parameter Group Number(FCU:FECAh)";
CM_ SG_ 2565603266 SequenceNum_FCU2 "TP_DT(Transport Protocol Data Transfer)-Package Identification";
CM_ SG_ 2565603266 PacketizedData_FCU2 "TP_DT message data";
CM_ SG_ 2365531852 VCU_HS01Msg_Crc "Crc Signal for E2E Protection";
CM_ SG_ 2365531852 VCU_HS01Msg_SeqNum "Sequence Number Signal for E2E Protection";
CM_ SG_ 2365531852 Vcu_FcRunCmd_Fc1 "FuelCell Run/Stop Command";
CM_ SG_ 2365531852 Vcu_FcStpCmd_Fc1 "Fuelcell Idle stop(Fc Stop) Command signal";
CM_ SG_ 2365531852 Vcu_IsoRestDtecReq_Fc1 "Electrical Isolation resistance detection request";
CM_ SG_ 2365531852 Vcu_FcPwrMinCmd_Fc1 "Fc Power Minimize command";
CM_ SG_ 2365531852 Vcu_FcPwrReq_Fc1 "Fc Power request(kw)(Demand power request)";
CM_ SG_ 2365531852 Vcu_HvFltEmgSdReq_Fc1 "Fc shutdown immediately(High Voltage Fault)";
CM_ SG_ 2365531852 Vcu_TnkClzEmgSdReq_Fc1 "Fc Emergency shutdown request(Tank close immediately)";
CM_ SG_ 2365532108 VCU_HS02Msg_Crc "Crc Signal for E2E Protection";
CM_ SG_ 2365532108 VCU_HS02Msg_SeqNum "Sequence Number Signal for E2E Protection";
CM_ SG_ 2365532108 Vcu_FcRunCmd_Fc2 "FuelCell Run/Stop Command";
CM_ SG_ 2365532108 Vcu_FcStpCmd_Fc2 "Fuelcell Idle stop(Fc Stop) Command signal";
CM_ SG_ 2365532108 Vcu_IsoRestDtecReq_Fc2 "Electrical Isolation resistance detection request";
CM_ SG_ 2365532108 Vcu_FcPwrMinCmd_Fc2 "Fc Power Minimize command";
CM_ SG_ 2365532108 Vcu_FcPwrReq_Fc2 "Fc Power request(kw)(Demand power request)";
CM_ SG_ 2365532108 Vcu_HvFltEmgSdReq_Fc2 "Fc shutdown immediately(High Voltage Fault)";
CM_ SG_ 2365532108 Vcu_TnkClzEmgSdReq_Fc2 "Fc Emergency shutdown request(Tank close immediately)";
CM_ SG_ 2365532364 VCU_HS03Msg_Crc "Crc Signal for E2E Protection";
CM_ SG_ 2365532364 VCU_HS03Msg_SeqNum "Sequence Number Signal for E2E Protection";
CM_ SG_ 2365532364 Vcu_VcuReady "VCU Ready상태";
CM_ SG_ 2365532364 Vcu_VehRdy "차량주행가능상태(클러스터 EVREAY)";
CM_ SG_ 2365532364 Vcu_AmbiTemp "외기온도센서값";
CM_ SG_ 2365532364 Vcu_WhlBasedSpd "Fc Coolant low level(낸각수부족:1)";
CM_ SG_ 2365532364 Vcu_HvBatSoc "고전압배터리 SOC";
CM_ SG_ 2365532364 Vcu_HvBatDchLmt_W "고전압배터리 최대방전limit";
CM_ SG_ 2566854604 VCU_HS04Msg_Crc "Crc Signal for E2E Protection";
CM_ SG_ 2566854604 VCU_HS04Msg_SeqNum "Sequence Number Signal for E2E Protection";
CM_ SG_ 2566854604 Vcu_FanFlt "라디에이터팬고장";
CM_ SG_ 2566854604 Vcu_FanRpmCmd "라디에이터팬 rpm command";
CM_ SG_ 2566854604 Vcu_FanRpmFb "라디에이터팬 rpm F/B";
CM_ SG_ 2566854604 Vcu_HsMaxPrmPwrLmt_Fc1 "Highside max permission power limit(Fcu1)";
CM_ SG_ 2566854604 Vcu_HsMaxPrmPwrLmtFc2 "Highside max permission power limit(Fcu2)";
CM_ SG_ 2365532620 VCU_HS05Msg_Crc "Crc Signal for E2E Protection";
CM_ SG_ 2365532620 VCU_HS05Msg_SeqNum "Sequence Number Signal for E2E Protection";
CM_ SG_ 2365532620 VCU_H2MidOrs "H2 Regulated Line Pressure";
CM_ SG_ 2365532620 VCU_DrvCyc "VCU Drive Cycle(DC)";
CM_ SG_ 2566854860 VCU_HS06Msg_Crc "Crc Signal for E2E Protection";
CM_ SG_ 2566854860 VCU_HS06Msg_SeqNum "Sequence Number Signal for E2E Protection";
CM_ SG_ 2583626017 FCU_HMSEn "Valve Open Command";
CM_ SG_ 2566848786 HMS1_PreMaxNo "Hydrogen peak pressure sensor code";
CM_ SG_ 2566848786 HMS1_LeakMaxNo "Highest concentration of hydragen leakage sensor";
CM_ SG_ 2566848786 HMS1_ConMaxNo "Hydrogen peak concentration sensor code";
CM_ SG_ 2566849042 HMS2_TankTempMax "Max temp at the entrance of the hydrogen bottle";
CM_ SG_ 2566849042 HMS2_TankTempMaxNo "Max temp at entrance of hydragen bottle";
CM_ SG_ 2566849042 HMS2_TankTempMin "Highest temp hydrogen bottle number";
CM_ SG_ 2566849042 HMS2_TankTempMinNo "Min temp at the inlet of the hydrogen bottle";
CM_ SG_ 2566849042 HMS2_TankTepAvr "Average temp at the hydrogen bottle inlet";
CM_ SG_ 2566849298 HMS3_HVOffReq "Request shut off high oressure";
CM_ SG_ 2566849298 HMS3_ValveOff_Req "When it detects a level2 or 3";
CM_ SG_ 2566849298 HMS3_FaultGrade "Failure code";
CM_ SG_ 2566849298 HMS3_Life "Life count";
CM_ SG_ 2566849298 HMS3_ValveStatus "Bottle Inlet Valve Status";
CM_ SG_ 2566849298 HMS3_Status "System State";
CM_ SG_ 2566849298 HMS3_LowPrs "Low Pressure";
CM_ SG_ 2566849298 HMS3_Soc "Hydrogen Residue ratio";
CM_ SG_ 2566849298 HMS3_FaultCode "Failure code";
CM_ SG_ 2566849810 HMS5_HyMassAvailable "DTE연산";
CM_ SG_ 2566886895 McuResetReason "BSW내부에서처리(API에 없음)";
CM_ SG_ 2566886895 CpuLoadPeak "BSW내부에서처리(API에 없음)";
CM_ SG_ 2566886895 CpuLoadCurrentPeak "BSW내부에서처리(API에 없음)";
CM_ SG_ 2566886895 ITLoadPeak "BSW내부에서처리(API에 없음)";
CM_ SG_ 2566886895 ITLoadCurrentPeak "BSW내부에서처리(API에 없음)";
CM_ SG_ 2566886895 MainStackUsed "BSW내부에서처리(API에 없음)";
CM_ SG_ 2566886895 CSAUsed "BSW내부에서처리(API에 없음)";
CM_ SG_ 2566887151 VcuAsw10msTask_us "BSW내부에서처리(API에 없음)";
CM_ SG_ 2566887151 VcuAsw100msTask_us "BSW내부에서처리(API에 없음)";
CM_ SG_ 2566887151 StateManagerTask_us "BSW내부에서처리(API에 없음)";
CM_ SG_ 2566887151 IoConverterTask_us "BSW내부에서처리(API에 없음)";
CM_ SG_ 2566843631 VINData "BSW에서 처리";
CM_ SG_ 2565668847 ControlByte_VCU_bsw "BSW에서 처리";
CM_ SG_ 2565668847 TotalMessageSize_VCU_bsw "BSW에서 처리";
CM_ SG_ 2565668847 TotalNumberOfPacket_VCU_bsw "BSW에서 처리";
CM_ SG_ 2565668847 PGNumber_VCU_bsw "BSW에서 처리";
CM_ SG_ 2565603311 SequenceNum_VCU_bsw "BSW에서 처리";
CM_ SG_ 2565603311 PacketizedData_VCU_bsw "BSW에서 처리";

BA_DEF_ "BusType" STRING;
BA_DEF_ BU_ "NmStationAddress" HEX 0 255;
BA_DEF_ BO_ "VFrameFormat" ENUM "StandardCAN","ExtendedCAN","reserved","J1939PG","reserved","reserved","reserved","reserved","reserved","reserved","reserved","reserved","reserved","reserved","StandardCAN_FD","ExtendedCAN_FD";
BA_DEF_ BO_ "GenMsgCycleTime" INT 0 200000;
BA_DEF_ BO_ "GenMsgSendType" ENUM "Cyclic","NoMsgSendType";
BA_DEF_ BO_ "GenMsgNrOfRepetition" INT 0 100;
BA_DEF_ BO_ "TpJ1939VarDlc" ENUM "No","Yes";
BA_DEF_ BO_ "GenMsgDelayTime" INT 0 1000;
BA_DEF_ BO_ "GenMsgRequestable" INT 0 1;
BA_DEF_ BO_ "GenMsgILSupport" ENUM "No","Yes";
BA_DEF_ SG_ "GenSigSendType" ENUM "NotUsed","OnWrite","OnWriteWithRepetition","OnChange","OnChangeWithRepetition","IfActive","IfActiveWithRepetition","NoSigSendType";
BA_DEF_ SG_ "GenSigStartValue" INT 0 100000;

BA_DEF_DEF_ "BusType" "CAN";
BA_DEF_DEF_ "NmStationAddress" 0;
BA_DEF_DEF_ "VFrameFormat" "StandardCAN";
BA_DEF_DEF_ "GenMsgCycleTime" 0;
BA_DEF_DEF_ "GenMsgSendType" "NoMsgSendType";
BA_DEF_DEF_ "GenMsgNrOfRepetition" 0;
BA_DEF_DEF_ "TpJ1939VarDlc" "No";
BA_DEF_DEF_ "GenMsgDelayTime" 0;
BA_DEF_DEF_ "GenMsgRequestable" 0;
BA_DEF_DEF_ "GenMsgILSupport" "Yes";
BA_DEF_DEF_ "GenSigSendType" "NoSigSendType";
BA_DEF_DEF_ "GenSigStartValue" 0;

BA_ "NmStationAddress" BU_ FCU1 193;
BA_ "NmStationAddress" BU_ FCU2 194;
BA_ "NmStationAddress" BU_ VCU 239;
BA_ "NmStationAddress" BU_ FDC1 210;
BA_ "NmStationAddress" BU_ FDC2 211;
BA_ "NmStationAddress" BU_ HMS 18;
BA_ "NmStationAddress" BU_ Tester 249;
BA_ "NmStationAddress" BU_ TBOX 74;
BA_ "VFrameFormat" BO_ 2365526209 3;
BA_ "GenMsgCycleTime" BO_ 2365526209 10;
BA_ "GenMsgSendType" BO_ 2365526209 0;
BA_ "GenMsgRequestable" BO_ 2365526209 1;
BA_ "VFrameFormat" BO_ 2365526465 1;
BA_ "GenMsgCycleTime" BO_ 2365526465 10;
BA_ "GenMsgSendType" BO_ 2365526465 0;
BA_ "GenMsgRequestable" BO_ 2365526465 1;
BA_ "VFrameFormat" BO_ 2365526721 3;
BA_ "GenMsgCycleTime" BO_ 2365526721 100;
BA_ "GenMsgSendType" BO_ 2365526721 0;
BA_ "GenMsgRequestable" BO_ 2365526721 1;
BA_ "VFrameFormat" BO_ 2365527233 1;
BA_ "GenMsgCycleTime" BO_ 2365527233 100;
BA_ "GenMsgSendType" BO_ 2365527233 0;
BA_ "GenMsgRequestable" BO_ 2365527233 1;
BA_ "VFrameFormat" BO_ 2365527489 3;
BA_ "GenMsgCycleTime" BO_ 2365527489 100;
BA_ "GenMsgSendType" BO_ 2365527489 0;
BA_ "GenMsgRequestable" BO_ 2365527489 1;
BA_ "VFrameFormat" BO_ 2365527745 1;
BA_ "GenMsgCycleTime" BO_ 2365527745 100;
BA_ "GenMsgSendType" BO_ 2365527745 0;
BA_ "GenMsgRequestable" BO_ 2365527745 1;
BA_ "VFrameFormat" BO_ 2365528001 3;
BA_ "GenMsgCycleTime" BO_ 2365528001 100;
BA_ "GenMsgSendType" BO_ 2365528001 0;
BA_ "GenMsgRequestable" BO_ 2365528001 1;
BA_ "VFrameFormat" BO_ 2365528257 1;
BA_ "GenMsgCycleTime" BO_ 2365528257 10;
BA_ "GenMsgSendType" BO_ 2365528257 0;
BA_ "GenMsgRequestable" BO_ 2365528257 1;
BA_ "VFrameFormat" BO_ 2566834881 3;
BA_ "TpJ1939VarDlc" BO_ 2566834881 1;
BA_ "GenMsgRequestable" BO_ 2566834881 1;
BA_ "VFrameFormat" BO_ 2565668801 1;
BA_ "GenMsgRequestable" BO_ 2565668801 1;
BA_ "VFrameFormat" BO_ 2565603265 1;
BA_ "GenMsgRequestable" BO_ 2565603265 1;
BA_ "VFrameFormat" BO_ 2365526210 3;
BA_ "GenMsgCycleTime" BO_ 2365526210 10;
BA_ "GenMsgSendType" BO_ 2365526210 0;
BA_ "GenMsgRequestable" BO_ 2365526210 1;
BA_ "VFrameFormat" BO_ 2365526466 1;
BA_ "GenMsgCycleTime" BO_ 2365526466 10;
BA_ "GenMsgSendType" BO_ 2365526466 0;
BA_ "GenMsgRequestable" BO_ 2365526466 1;
BA_ "VFrameFormat" BO_ 2365526722 3;
BA_ "GenMsgCycleTime" BO_ 2365526722 100;
BA_ "GenMsgSendType" BO_ 2365526722 0;
BA_ "GenMsgRequestable" BO_ 2365526722 1;
BA_ "VFrameFormat" BO_ 2365527234 3;
BA_ "GenMsgCycleTime" BO_ 2365527234 100;
BA_ "GenMsgSendType" BO_ 2365527234 0;
BA_ "GenMsgRequestable" BO_ 2365527234 1;
BA_ "VFrameFormat" BO_ 2365527490 3;
BA_ "GenMsgCycleTime" BO_ 2365527490 100;
BA_ "GenMsgSendType" BO_ 2365527490 0;
BA_ "GenMsgRequestable" BO_ 2365527490 1;
BA_ "VFrameFormat" BO_ 2365527746 3;
BA_ "GenMsgCycleTime" BO_ 2365527746 100;
BA_ "GenMsgSendType" BO_ 2365527746 0;
BA_ "GenMsgRequestable" BO_ 2365527746 1;
BA_ "VFrameFormat" BO_ 2365528002 3;
BA_ "GenMsgCycleTime" BO_ 2365528002 100;
BA_ "GenMsgSendType" BO_ 2365528002 0;
BA_ "GenMsgRequestable" BO_ 2365528002 1;
BA_ "VFrameFormat" BO_ 2365528258 3;
BA_ "GenMsgCycleTime" BO_ 2365528258 10;
BA_ "GenMsgSendType" BO_ 2365528258 0;
BA_ "GenMsgRequestable" BO_ 2365528258 1;
BA_ "VFrameFormat" BO_ 2566834882 3;
BA_ "TpJ1939VarDlc" BO_ 2566834882 1;
BA_ "GenMsgRequestable" BO_ 2566834882 1;
BA_ "VFrameFormat" BO_ 2565668802 1;
BA_ "GenMsgRequestable" BO_ 2565668802 1;
BA_ "VFrameFormat" BO_ 2565603266 1;
BA_ "GenMsgRequestable" BO_ 2565603266 1;
BA_ "VFrameFormat" BO_ 2365531852 1;
BA_ "GenMsgCycleTime" BO_ 2365531852 10;
BA_ "GenMsgSendType" BO_ 2365531852 0;
BA_ "GenMsgRequestable" BO_ 2365531852 1;
BA_ "VFrameFormat" BO_ 2365532108 1;
BA_ "GenMsgCycleTime" BO_ 2365532108 10;
BA_ "GenMsgSendType" BO_ 2365532108 0;
BA_ "GenMsgRequestable" BO_ 2365532108 1;
BA_ "VFrameFormat" BO_ 2365532364 3;
BA_ "GenMsgCycleTime" BO_ 2365532364 100;
BA_ "GenMsgSendType" BO_ 2365532364 0;
BA_ "GenMsgRequestable" BO_ 2365532364 1;
BA_ "VFrameFormat" BO_ 2566854604 1;
BA_ "GenMsgCycleTime" BO_ 2566854604 100;
BA_ "GenMsgSendType" BO_ 2566854604 0;
BA_ "GenMsgRequestable" BO_ 2566854604 1;
BA_ "VFrameFormat" BO_ 2365532620 3;
BA_ "GenMsgCycleTime" BO_ 2365532620 100;
BA_ "GenMsgSendType" BO_ 2365532620 0;
BA_ "GenMsgRequestable" BO_ 2365532620 1;
BA_ "VFrameFormat" BO_ 2566854860 1;
BA_ "GenMsgCycleTime" BO_ 2566854860 100;
BA_ "GenMsgSendType" BO_ 2566854860 0;
BA_ "GenMsgRequestable" BO_ 2566854860 1;
BA_ "VFrameFormat" BO_ 2566865647 1;
BA_ "GenMsgCycleTime" BO_ 2566865647 100;
BA_ "GenMsgSendType" BO_ 2566865647 0;
BA_ "GenMsgRequestable" BO_ 2566865647 1;
BA_ "VFrameFormat" BO_ 2566848722 1;
BA_ "GenMsgCycleTime" BO_ 2566848722 10;
BA_ "GenMsgSendType" BO_ 2566848722 0;
BA_ "GenMsgRequestable" BO_ 2566848722 1;
BA_ "VFrameFormat" BO_ 2566848978 1;
BA_ "GenMsgCycleTime" BO_ 2566848978 10;
BA_ "GenMsgSendType" BO_ 2566848978 0;
BA_ "GenMsgRequestable" BO_ 2566848978 1;
BA_ "VFrameFormat" BO_ 2566848723 1;
BA_ "GenMsgCycleTime" BO_ 2566848723 10;
BA_ "GenMsgSendType" BO_ 2566848723 0;
BA_ "GenMsgRequestable" BO_ 2566848723 1;
BA_ "VFrameFormat" BO_ 2566848979 1;
BA_ "GenMsgCycleTime" BO_ 2566848979 10;
BA_ "GenMsgSendType" BO_ 2566848979 0;
BA_ "GenMsgRequestable" BO_ 2566848979 1;
BA_ "VFrameFormat" BO_ 2583626017 1;
BA_ "GenMsgCycleTime" BO_ 2583626017 100;
BA_ "GenMsgSendType" BO_ 2583626017 0;
BA_ "GenMsgRequestable" BO_ 2583626017 1;
BA_ "VFrameFormat" BO_ 2566848786 1;
BA_ "GenMsgCycleTime" BO_ 2566848786 100;
BA_ "GenMsgSendType" BO_ 2566848786 0;
BA_ "GenMsgRequestable" BO_ 2566848786 1;
BA_ "VFrameFormat" BO_ 2566849042 1;
BA_ "GenMsgCycleTime" BO_ 2566849042 100;
BA_ "GenMsgSendType" BO_ 2566849042 0;
BA_ "GenMsgRequestable" BO_ 2566849042 1;
BA_ "VFrameFormat" BO_ 2566849298 1;
BA_ "GenMsgCycleTime" BO_ 2566849298 100;
BA_ "GenMsgSendType" BO_ 2566849298 0;
BA_ "GenMsgRequestable" BO_ 2566849298 1;
BA_ "VFrameFormat" BO_ 2566849810 1;
BA_ "GenMsgCycleTime" BO_ 2566849810 100;
BA_ "GenMsgSendType" BO_ 2566849810 0;
BA_ "GenMsgRequestable" BO_ 2566849810 1;
BA_ "VFrameFormat" BO_ 2566850066 1;
BA_ "GenMsgCycleTime" BO_ 2566850066 5000;
BA_ "GenMsgSendType" BO_ 2566850066 0;
BA_ "GenMsgRequestable" BO_ 2566850066 1;
BA_ "VFrameFormat" BO_ 2566886895 1;
BA_ "GenMsgCycleTime" BO_ 2566886895 1000;
BA_ "GenMsgSendType" BO_ 2566886895 0;
BA_ "GenMsgRequestable" BO_ 2566886895 1;
BA_ "VFrameFormat" BO_ 2566887151 1;
BA_ "GenMsgCycleTime" BO_ 2566887151 1000;
BA_ "GenMsgSendType" BO_ 2566887151 0;
BA_ "GenMsgRequestable" BO_ 2566887151 1;
BA_ "VFrameFormat" BO_ 2499748089 1;
BA_ "GenMsgSendType" BO_ 2499748089 0;
BA_ "GenMsgRequestable" BO_ 2499748089 1;
BA_ "VFrameFormat" BO_ 2499748079 1;
BA_ "GenMsgCycleTime" BO_ 2499748079 100;
BA_ "GenMsgSendType" BO_ 2499748079 0;
BA_ "GenMsgRequestable" BO_ 2499748079 1;
BA_ "VFrameFormat" BO_ 2565530785 1;
BA_ "GenMsgRequestable" BO_ 2565530785 1;
BA_ "GenSigSendType" SG_ 2565530785 TBOX_VIN_Req 1;
BA_ "VFrameFormat" BO_ 2566843631 3;
BA_ "GenMsgNrOfRepetition" BO_ 2566843631 1;
BA_ "GenMsgRequestable" BO_ 2566843631 1;
BA_ "GenSigSendType" SG_ 2566843631 VINData 1;
BA_ "VFrameFormat" BO_ 2565668847 1;
BA_ "GenMsgNrOfRepetition" BO_ 2565668847 2;
BA_ "GenMsgRequestable" BO_ 2565668847 1;
BA_ "VFrameFormat" BO_ 2565603311 1;
BA_ "GenMsgRequestable" BO_ 2565603311 1;
